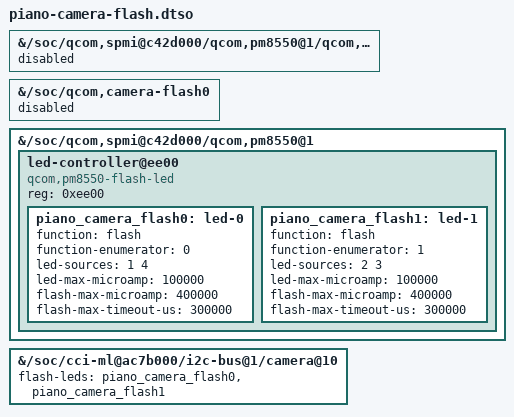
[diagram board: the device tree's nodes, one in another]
// SPDX-License-Identifier: GPL-2.0-only OR BSD-2-Clause
/dts-v1/;
/plugin/;

/*
 * PM8550 flash controller on SID 1. Each LED uses two current sinks.
 * Keep the board's total LED current budget when assigning the two pairs.
 */
/ {
	fragment@0 {
		target-path = "/soc/qcom,spmi@c42d000/qcom,pm8550@1/qcom,flash_led@ee00";
		__overlay__ {
			status = "disabled";
		};
	};

	fragment@1 {
		target-path = "/soc/qcom,camera-flash0";
		__overlay__ {
			status = "disabled";
		};
	};

	fragment@2 {
		target-path = "/soc/qcom,spmi@c42d000/qcom,pm8550@1";
		__overlay__ {
			#address-cells = <1>;
			#size-cells = <0>;

			led-controller@ee00 {
				compatible = "qcom,pm8550-flash-led", "qcom,spmi-flash-led";
				reg = <0xee00>;
				status = "okay";

				piano_camera_flash0: led-0 {
					function = "flash";
					function-enumerator = <0>;
					led-sources = <1 4>;
					led-max-microamp = <100000>;
					flash-max-microamp = <400000>;
					flash-max-timeout-us = <300000>;
				};

				piano_camera_flash1: led-1 {
					function = "flash";
					function-enumerator = <1>;
					led-sources = <2 3>;
					led-max-microamp = <100000>;
					flash-max-microamp = <400000>;
					flash-max-timeout-us = <300000>;
				};
			};
		};
	};

	fragment@3 {
		target-path = "/soc/cci-ml@ac7b000/i2c-bus@1/camera@10";
		__overlay__ {
			/* S5KJN1 uses the standard sensor async notifier. */
			flash-leds = <&piano_camera_flash0 &piano_camera_flash1>;
		};
	};
};
